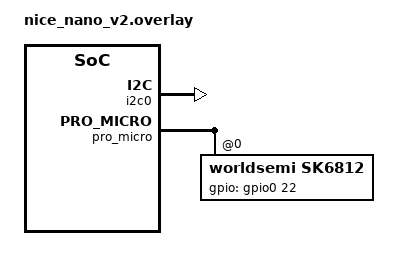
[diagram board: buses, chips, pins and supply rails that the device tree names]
/* Sofle Choc v2.1 — Wired TRRS (UART) + OLED + RGB
 *
 * Pins chosen based on your nRF52840 labels:
 *   UART TX = P0.17 (017)
 *   UART RX = P0.20 (020)
 *   sk6812  = P0.22 (022)
 */

&i2c0 {          /* OLEDs use I2C SSD1306 via Sofle shield */
    status = "okay";
};



/* ----- sk6812/SK6812 LED chain -----
 * Update chain-length to your actual per-half count.
 */
&pro_micro {
    sk6812: sk6812@0 {
        compatible = "worldsemi,sk6812";
        label = "sk6812";
        gpios = <&gpio0 22 0>;   /* P0.22 (022) */
        chain-length = <26>;     /* Adjust to your actual per-half LED count. */
        status = "okay";
        /* Most common for sk6812/SK6812 */
        color-mapping = <LED_COLOR_ID_GREEN LED_COLOR_ID_RED LED_COLOR_ID_BLUE>;

    };
};
